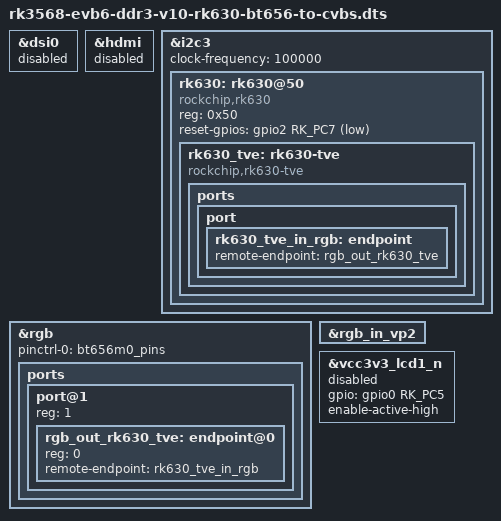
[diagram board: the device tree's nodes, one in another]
// SPDX-License-Identifier: (GPL-2.0+ OR MIT)
/*
 * Copyright (c) 2020 Rockchip Electronics Co., Ltd.
 */

#include <dt-bindings/display/media-bus-format.h>
#include "rk3568-evb6-ddr3-v10.dtsi"
#include "rk3568-android.dtsi"

&dsi0 {
	status = "disabled";
};

&hdmi {
	status = "disabled";
};

&i2c3 {
	status = "okay";
	clock-frequency = <100000>;

	rk630: rk630@50 {
		compatible = "rockchip,rk630";
		reg = <0x50>;
		reset-gpios = <&gpio2 RK_PC7 GPIO_ACTIVE_LOW>;
		status = "okay";

		rk630_tve: rk630-tve {
			compatible = "rockchip,rk630-tve";
			status = "okay";

			ports {
				port {
					rk630_tve_in_rgb: endpoint {
						remote-endpoint = <&rgb_out_rk630_tve>;
					};
				};
			};
		};
	};
};

&rgb {
	pinctrl-names = "default";
	pinctrl-0 = <&bt656m0_pins>; /* bt656m0_pins or bt656m1_pins */
	status = "okay";

	ports {
		port@1 {
			reg = <1>;
			#address-cells = <1>;
			#size-cells = <0>;

			rgb_out_rk630_tve: endpoint@0 {
				reg = <0>;
				remote-endpoint = <&rk630_tve_in_rgb>;
			};
		};
	};
};

&rgb_in_vp2 {
	status = "okay";
};

&vcc3v3_lcd1_n {
	status = "disabled";
	gpio = <&gpio0 RK_PC5 GPIO_ACTIVE_HIGH>;
	enable-active-high;
};
